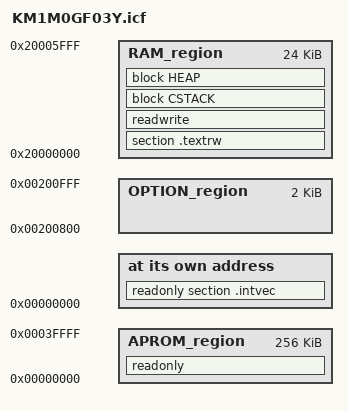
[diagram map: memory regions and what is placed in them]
/*###ICF### Section handled by ICF editor, don't touch! ****/
/*-Editor annotation file-*/
/* IcfEditorFile="$TOOLKIT_DIR$\config\ide\IcfEditor\cortex_v1_0.xml" */
/*-Specials-*/
define symbol __ICFEDIT_intvec_start__ = 0x00000000;
/*-Memory Regions-*/
define symbol __ICFEDIT_region_RAM_start__              = 0x20000000;
define symbol __ICFEDIT_region_RAM_end__                = 0x20005FFF;
define symbol __ICFEDIT_region_OPTION_start__           = 0x00200800;
define symbol __ICFEDIT_region_OPTION_end__             = 0x00200FFF;
define symbol __ICFEDIT_region_APROM_start__            = 0x00000000;
define symbol __ICFEDIT_region_APROM_end__              = 0x0003FFFF;
/*-Sizes-*/
define symbol __ICFEDIT_size_cstack__ = 0x400;
define symbol __ICFEDIT_size_heap__   = 0x800;
/**** End of ICF editor section. ###ICF###*/

/**** Special settings for target device ****/

/*- Define symbols -*/

/* Define the memory space of 4G bytes named "mem" */
define memory mem with size = 4G;

/*- Define region in memory -*/
define region APROM_region           = mem:[from __ICFEDIT_region_APROM_start__  to __ICFEDIT_region_APROM_end__];
define region OPTION_region          = mem:[from __ICFEDIT_region_OPTION_start__  to __ICFEDIT_region_OPTION_end__];
define region RAM_region             = mem:[from __ICFEDIT_region_RAM_start__ to __ICFEDIT_region_RAM_end__];

/*- Define block -*/
define block CSTACK    with alignment = 8, size = __ICFEDIT_size_cstack__   { };
define block HEAP      with alignment = 8, size = __ICFEDIT_size_heap__     { };

/*- Initialize type -*/
initialize by copy { readwrite };
do not initialize  { section .noinit };

/*- Set placement in memory or region -*/
place at address mem:__ICFEDIT_intvec_start__ { readonly section .intvec };

place in APROM_region   { readonly };
place in RAM_region  { section .textrw, readwrite, block CSTACK, block HEAP };
